# CY8C5267LTI_LP089 register map
File version: 0.1
CY8C52LP
Registers are 8-bit, read-write, no defined reset value unless marked. A register's access mark holds for its fields unless they carry their own. Offsets are from the block's base; lines under a group give offsets from that group; [hi:lo] are bit positions; {n}, {i} and the like mark numbered series; 'fields as' and 'values as' point back to an identical list; <NAME> marks a mode.

## Memory map
0x00000000 GPS — UART
0x00000000 UART

## GPS — UART
Base 0x00000000
0x40006427 RX_GPS_RX_ADDRESS1 — RX Address1 Register
0x40006437 RX_GPS_RX_ADDRESS2 — RX Address2 Register
0x40006447 RX_GPS_RX_DATA — RX Data Register
0x40006545 TX_GPS_TX_DATA — TX Data Register
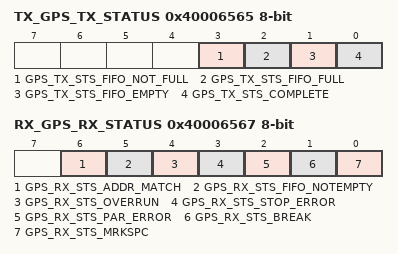
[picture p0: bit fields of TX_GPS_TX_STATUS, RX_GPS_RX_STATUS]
0x40006565 TX_GPS_TX_STATUS — TX status register
  [3] GPS_TX_STS_FIFO_NOT_FULL ro, [2] GPS_TX_STS_FIFO_FULL ro, [1] GPS_TX_STS_FIFO_EMPTY ro, [0] GPS_TX_STS_COMPLETE ro
0x40006567 RX_GPS_RX_STATUS — RX status register
  [6] GPS_RX_STS_ADDR_MATCH ro, [5] GPS_RX_STS_FIFO_NOTEMPTY ro, [4] GPS_RX_STS_OVERRUN ro, [3] GPS_RX_STS_STOP_ERROR ro, [2] GPS_RX_STS_PAR_ERROR ro, [1] GPS_RX_STS_BREAK ro, [0] GPS_RX_STS_MRKSPC ro

## UART
Base 0x00000000
0x40006444 TX_UART_TX_DATA — TX Data Register
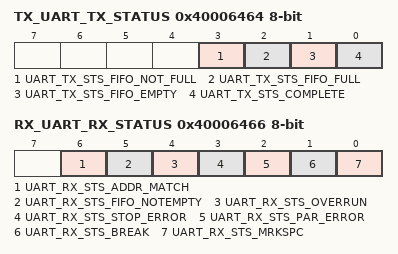
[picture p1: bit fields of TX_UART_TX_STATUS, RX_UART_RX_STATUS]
0x40006464 TX_UART_TX_STATUS — TX status register
  [3] UART_TX_STS_FIFO_NOT_FULL ro, [2] UART_TX_STS_FIFO_FULL ro, [1] UART_TX_STS_FIFO_EMPTY ro, [0] UART_TX_STS_COMPLETE ro
0x40006466 RX_UART_RX_STATUS — RX status register
  [6] UART_RX_STS_ADDR_MATCH ro, [5] UART_RX_STS_FIFO_NOTEMPTY ro, [4] UART_RX_STS_OVERRUN ro, [3] UART_RX_STS_STOP_ERROR ro, [2] UART_RX_STS_PAR_ERROR ro, [1] UART_RX_STS_BREAK ro, [0] UART_RX_STS_MRKSPC ro
0x40006526 RX_UART_RX_ADDRESS1 — RX Address1 Register
0x40006536 RX_UART_RX_ADDRESS2 — RX Address2 Register
0x40006546 RX_UART_RX_DATA — RX Data Register
